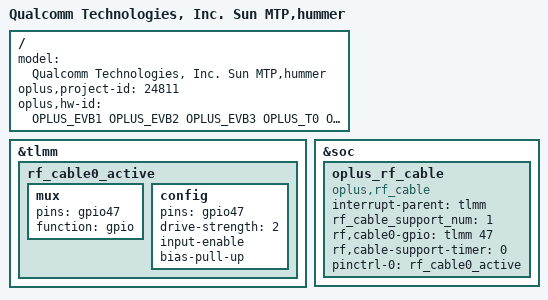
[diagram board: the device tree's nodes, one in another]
/dts-v1/;
/plugin/;
#include <dt-bindings/oplus/hw-id.h>
#include "../qcom/sun-mtp-v8-overlay.dts"
#include "sun_overlay_common.dtsi"
#include "hummer_overlay_common.dtsi"
#include "oplus_misc/oplus-misc-24811.dtsi"
#include "oplus_fp/oplus_fp_24811.dtsi"
#include "tp/hummer-oplus-tp-24811.dtsi"
#include "oplus_chg/oplus-chg-24811.dtsi"
#include "sensor/hummer-sensor-24811.dtsi"
#include "oplus_nfc/hummer_nfc.dtsi"
#include "mm/hummer-24811-sun-mm.dtsi"

/ {
    model = "Qualcomm Technologies, Inc. Sun MTP,hummer";

    oplus,project-id = <24811>;
    oplus,hw-id = <OPLUS_EVB1 OPLUS_EVB2 OPLUS_EVB3 OPLUS_T0 OPLUS_T1 OPLUS_EVT1 OPLUS_EVT2 OPLUS_DVT1 OPLUS_DVT2 OPLUS_PVT1>;
};

&tlmm {
    //#ifdef OPLUS_FEATURE_RF_CABLE_DETECT
    rf_cable0_active: rf_cable0_active {
        mux {
            pins = "gpio47";
            function = "gpio";
        };
        config {
            pins = "gpio47";
            drive-strength = <2>;
            input-enable;
            bias-pull-up;
        };
    };
    //#endif /* OPLUS_FEATURE_RF_CABLE_DETECT */
};

&soc {
    //#ifdef OPLUS_FEATURE_RF_CABLE_DETECT
    oplus_rf_cable {
        compatible = "oplus,rf_cable";
        interrupt-parent = <&tlmm>;
        rf_cable_support_num = <1>;
        rf,cable0-gpio = <&tlmm 47 0>;
        rf,cable-support-timer = <0>;
        pinctrl-names = "rf_cable_active";
        pinctrl-0 = <&rf_cable0_active>;
    };
    //#endif /* OPLUS_FEATURE_RF_CABLE_DETECT */
};
